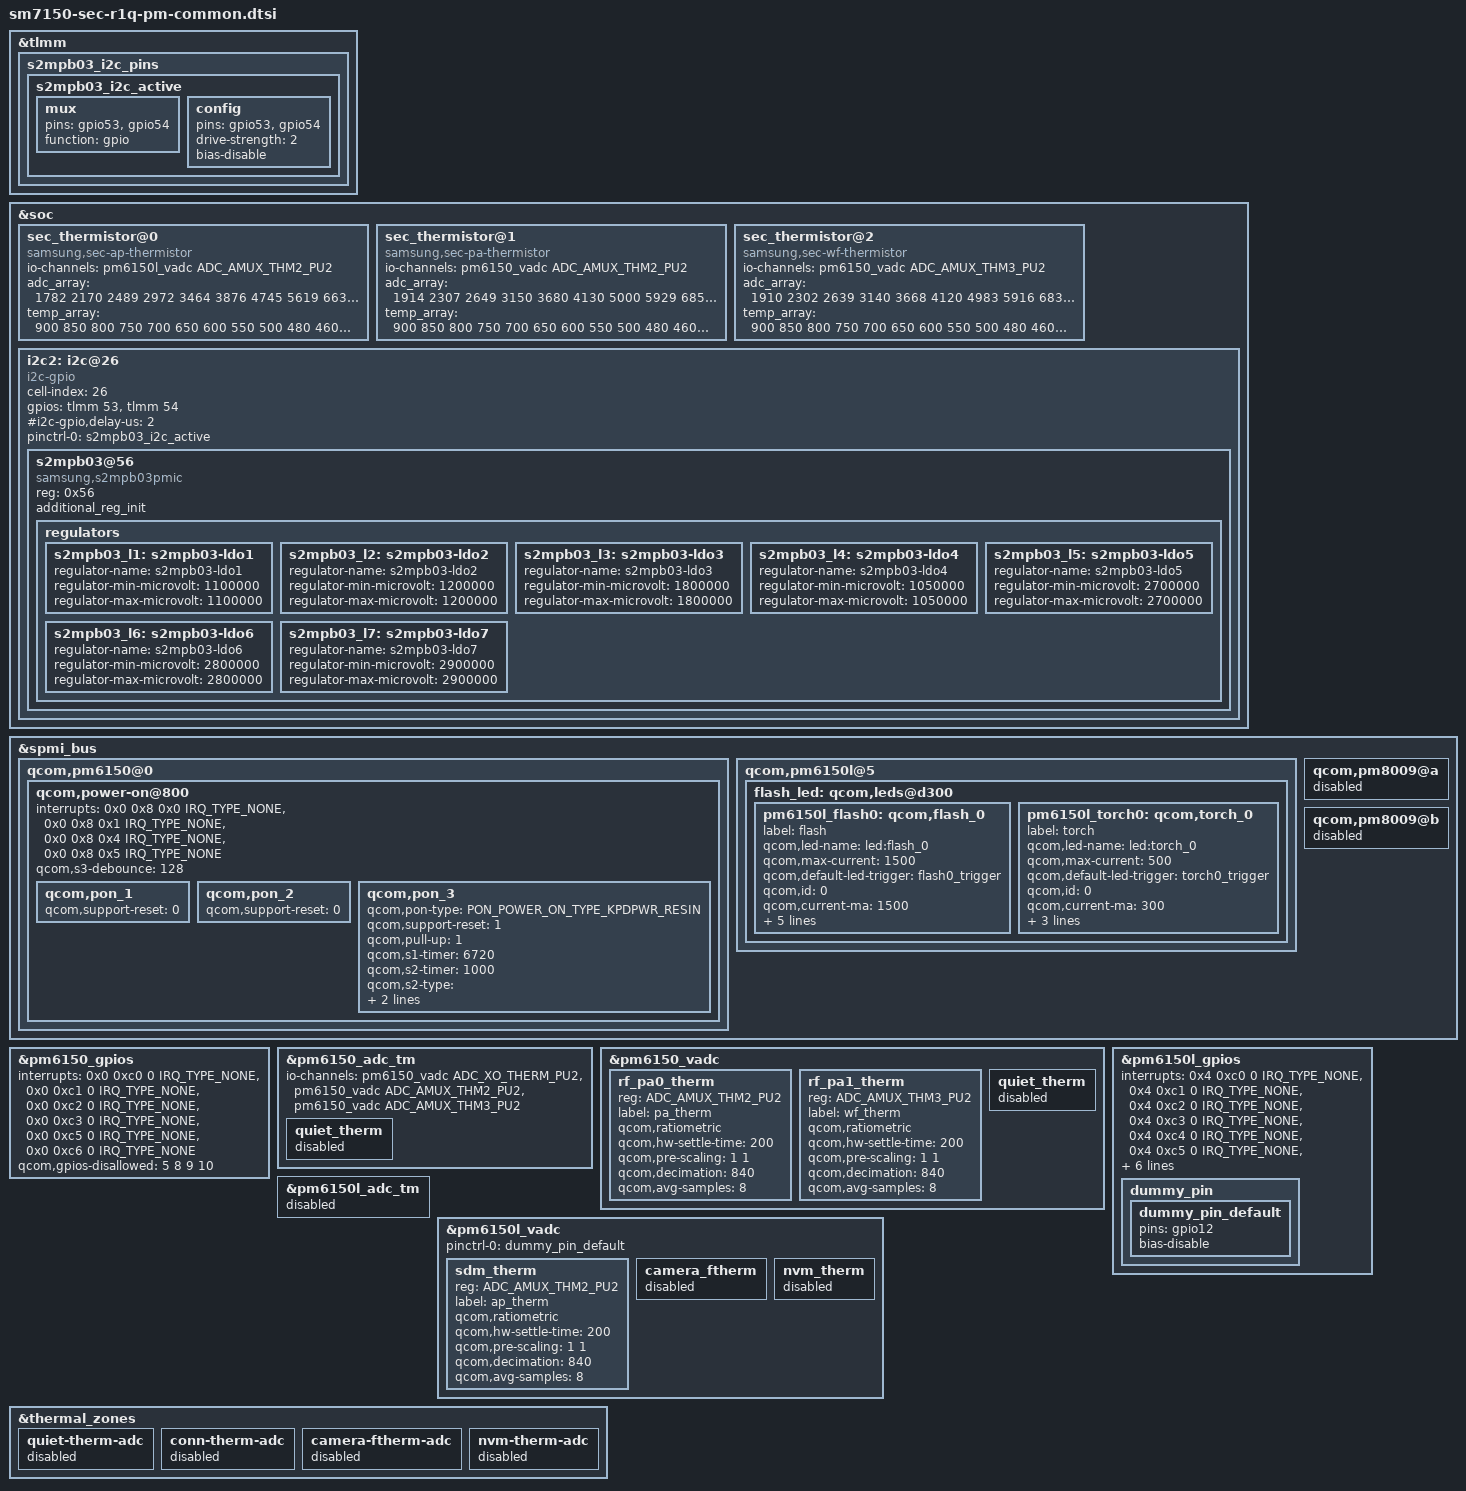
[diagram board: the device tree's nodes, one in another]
/* Copyright (c) 2018, The Linux Foundation. All rights reserved.
 *
 * This program is free software; you can redistribute it and/or modify
 * it under the terms of the GNU General Public License version 2 and
 * only version 2 as published by the Free Software Foundation.
 *
 * This program is distributed in the hope that it will be useful,
 * but WITHOUT ANY WARRANTY; without even the implied warranty of
 * MERCHANTABILITY or FITNESS FOR A PARTICULAR PURPOSE.  See the
 * GNU General Public License for more details.
 */
#include <dt-bindings/input/qcom,qpnp-power-on.h>

&tlmm {
	s2mpb03_i2c_pins {
		s2mpb03_i2c_active: s2mpb03_i2c_active {
			mux {
				pins = "gpio53", "gpio54";
				function = "gpio";
			};
			config {
				pins = "gpio53", "gpio54";
				drive-strength = <2>;
				bias-disable;
			};
		};
	};
};

&soc {
	/* AP Thermistor table */
	sec_thermistor@0 {
		compatible = "samsung,sec-ap-thermistor";
		status = "okay";
		io-channels = <&pm6150l_vadc ADC_AMUX_THM2_PU2>;
		io-channel-names = "ap_therm";
		adc_array = <1782 2170 2489 2972 3464 3876 4745
					5619 6633 7099 7520 7972 8464 9020 9592 10167 10771 11357 11753
					13464 15121 16708 18393 20103 21419 23021 24228 25379 26099>;
		temp_array = <900 850 800 750 700 650 600
					550 500 480 460 440 420 400 380 360 340 320 300
					250 200 150 100 50 0 (-50) (-100) (-150) (-200)>;
	};

	/* PA Thermistor table */
	sec_thermistor@1 {
		compatible = "samsung,sec-pa-thermistor";
		status = "okay";
		io-channels = <&pm6150_vadc ADC_AMUX_THM2_PU2>;
		io-channel-names = "pa_therm";
		adc_array = <1914 2307 2649 3150 3680 4130 5000
					5929 6853 7280 7731 8225 8693 9262 9914 10473 11055 11604 12445
					14125 15966 17690 19306 20877 22060 23411 24563 25536 26339>;
		temp_array = <900 850 800 750 700 650 600
					550 500 480 460 440 420 400 380 360 340 320 300
					250 200 150 100 50 0 (-50) (-100) (-150) (-200)>;
	};

	/* WiFi Thermistor table */
	sec_thermistor@2 {
		compatible = "samsung,sec-wf-thermistor";
		status = "okay";
		io-channels = <&pm6150_vadc ADC_AMUX_THM3_PU2>;
		io-channel-names = "wf_therm";
		adc_array = <1910 2302 2639 3140 3668 4120 4983
					5916 6835 7388 7240 8208 8675 9240 9891 10452 11032 11578 12433
					14098 15940 17663 19280 20850 22029 23413 24540 25516 26317>;
		temp_array = <900 850 800 750 700 650 600
					550 500 480 460 440 420 400 380 360 340 320 300
					250 200 150 100 50 0 (-50) (-100) (-150) (-200)>;
	};

	/* S2MPB03 Camera PMIC */
	i2c2: i2c@26 {
		cell-index = <26>;
		compatible = "i2c-gpio";
		gpios = <&tlmm 53 0 /* sda */
				&tlmm 54 0 /* scl */
		>;
		#i2c-gpio,delay-us = <2>;
		#address-cells = <1>;
		#size-cells = <0>;

		pinctrl-names = "default";
		pinctrl-0 = <&s2mpb03_i2c_active>;

		/* S2MPB03 Camera PMIC */
		s2mpb03@56 {
			compatible = "samsung,s2mpb03pmic";
			reg = <0x56>;
			additional_reg_init;

			regulators {
				s2mpb03_l1: s2mpb03-ldo1 {
					regulator-name = "s2mpb03-ldo1";
					regulator-min-microvolt = <1100000>;
					regulator-max-microvolt = <1100000>;
				};

				s2mpb03_l2: s2mpb03-ldo2 {
					regulator-name = "s2mpb03-ldo2";
					regulator-min-microvolt = <1200000>;
					regulator-max-microvolt = <1200000>;
				};

				s2mpb03_l3: s2mpb03-ldo3 {
					regulator-name = "s2mpb03-ldo3";
					regulator-min-microvolt = <1800000>;
					regulator-max-microvolt = <1800000>;
				};

				s2mpb03_l4: s2mpb03-ldo4 {
					regulator-name = "s2mpb03-ldo4";
					regulator-min-microvolt = <1050000>;
					regulator-max-microvolt = <1050000>;
				};

				s2mpb03_l5: s2mpb03-ldo5 {
					regulator-name = "s2mpb03-ldo5";
					regulator-min-microvolt = <2700000>;
					regulator-max-microvolt = <2700000>;
				};

				s2mpb03_l6: s2mpb03-ldo6 {
					regulator-name = "s2mpb03-ldo6";
					regulator-min-microvolt = <2800000>;
					regulator-max-microvolt = <2800000>;
				};

				s2mpb03_l7: s2mpb03-ldo7 {
					regulator-name = "s2mpb03-ldo7";
					regulator-min-microvolt = <2900000>;
					regulator-max-microvolt = <2900000>;
				};
			};
		};
	};
};

&spmi_bus {
	qcom,pm6150@0 {
		qcom,power-on@800 {
			interrupts = <0x0 0x8 0x0 IRQ_TYPE_NONE>,
					<0x0 0x8 0x1 IRQ_TYPE_NONE>,
					<0x0 0x8 0x4 IRQ_TYPE_NONE>,
					<0x0 0x8 0x5 IRQ_TYPE_NONE>;
			interrupt-names = "kpdpwr", "resin",
					"resin-bark", "kpdpwr-resin-bark";
			qcom,s3-debounce = <128>;

			qcom,pon_1 {
				qcom,support-reset = <0>;
			};

			qcom,pon_2 {
				qcom,support-reset = <0>;
			};

			qcom,pon_3 {
				qcom,pon-type = <PON_POWER_ON_TYPE_KPDPWR_RESIN>;
				qcom,support-reset = <1>;
				qcom,pull-up = <1>;
				qcom,s1-timer = <6720>;
				qcom,s2-timer = <1000>;
				qcom,s2-type = <PON_POWER_OFF_TYPE_DVDD_HARD_RESET>;
				qcom,use-bark;
			};
		};
	};

	qcom,pm6150l@5 {
		flash_led: qcom,leds@d300 {
			pm6150l_flash0: qcom,flash_0 {
				label = "flash";
				qcom,led-name = "led:flash_0";
				qcom,max-current = <1500>;
				qcom,default-led-trigger = "flash0_trigger";
				qcom,id = <0>;
				qcom,current-ma = <1500>;
				qcom,duration-ms = <1280>;
				qcom,ires-ua = <12500>;
				qcom,hdrm-voltage-mv = <325>;
				qcom,hdrm-vol-hi-lo-win-mv = <100>;
				qcom,record-current-ma = <200>;
			};
			pm6150l_torch0: qcom,torch_0 {
				label = "torch";
				qcom,led-name = "led:torch_0";
				qcom,max-current = <500>;
				qcom,default-led-trigger = "torch0_trigger";
				qcom,id = <0>;
				qcom,current-ma = <300>;
				qcom,ires-ua = <12500>;
				qcom,hdrm-voltage-mv = <325>;
				qcom,hdrm-vol-hi-lo-win-mv = <100>;
			};
		};			
	};	
    
	qcom,pm8009@a {
		status = "disabled";
	};
	qcom,pm8009@b {
		status = "disabled";
	};
};

&pm6150_gpios {
	interrupts = <0x0 0xc0 0 IRQ_TYPE_NONE>,
		<0x0 0xc1 0 IRQ_TYPE_NONE>,
		<0x0 0xc2 0 IRQ_TYPE_NONE>,
		<0x0 0xc3 0 IRQ_TYPE_NONE>,
		<0x0 0xc5 0 IRQ_TYPE_NONE>,
		<0x0 0xc6 0 IRQ_TYPE_NONE>;

	interrupt-names = "pm6150_gpio1", "pm6150_gpio2",
		"pm6150_gpio3", "pm6150_gpio4",
		"pm6150_gpio6",
		"pm6150_gpio7";
	qcom,gpios-disallowed = <5 8 9 10>;
};

&pm6150_adc_tm {
	io-channels = <&pm6150_vadc ADC_XO_THERM_PU2>,
			<&pm6150_vadc ADC_AMUX_THM2_PU2>,
			<&pm6150_vadc ADC_AMUX_THM3_PU2>;

	quiet_therm {
		status = "disabled";
	};
};

&pm6150_vadc {
	rf_pa0_therm {
		reg = <ADC_AMUX_THM2_PU2>;
		label = "pa_therm";
		qcom,ratiometric;
		qcom,hw-settle-time = <200>;
		qcom,pre-scaling = <1 1>;
		qcom,decimation = <840>;
		qcom,avg-samples = <8>;
	};

	rf_pa1_therm {
		reg = <ADC_AMUX_THM3_PU2>;
		label = "wf_therm";
		qcom,ratiometric;
		qcom,hw-settle-time = <200>;
		qcom,pre-scaling = <1 1>;
		qcom,decimation = <840>;
		qcom,avg-samples = <8>;
	};

	quiet_therm {
		status = "disabled";
	};
};

&pm6150l_gpios {
	interrupts = <0x4 0xc0 0 IRQ_TYPE_NONE>,
			<0x4 0xc1 0 IRQ_TYPE_NONE>,
			<0x4 0xc2 0 IRQ_TYPE_NONE>,
			<0x4 0xc3 0 IRQ_TYPE_NONE>,
			<0x4 0xc4 0 IRQ_TYPE_NONE>,
			<0x4 0xc5 0 IRQ_TYPE_NONE>,
			<0x4 0xc7 0 IRQ_TYPE_NONE>,
			<0x4 0xc8 0 IRQ_TYPE_NONE>,
			<0x4 0xc9 0 IRQ_TYPE_NONE>,
			<0x4 0xca 0 IRQ_TYPE_NONE>,
			<0x4 0xcb 0 IRQ_TYPE_NONE>;
	interrupt-names = "pm6150l_gpio1", "pm6150l_gpio2",
			"pm6150l_gpio3", "pm6150l_gpio4",
			"pm6150l_gpio5", "pm6150l_gpio6",
			"pm6150l_gpio8", "pm6150l_gpio9",
			"pm6150l_gpio10", "pm6150l_gpio11",
			"pm6150l_gpio12";
	qcom,gpios-disallowed = <7>;

	dummy_pin {
		dummy_pin_default: dummy_pin_default {
			pins = "gpio12";
			bias-disable;
		};
	};
};

&pm6150l_adc_tm {
	status = "disabled";
/*	/delete-property/ io-channels;

	conn_therm {
		status = "disabled";
	};
	camera_ftherm {
		status = "disabled";
	};
	nvm_therm {
		status = "disabled";
	}; */
};

&pm6150l_vadc {
	pinctrl-0 = <&dummy_pin_default>;

	sdm_therm {
		reg = <ADC_AMUX_THM2_PU2>;
		label = "ap_therm";
		qcom,ratiometric;
		qcom,hw-settle-time = <200>;
		qcom,pre-scaling = <1 1>;
		qcom,decimation = <840>;
		qcom,avg-samples = <8>;
	};

	camera_ftherm {
		status = "disabled";
	};
	nvm_therm {
		status = "disabled";
	};
};

&thermal_zones {
	quiet-therm-adc {
		status = "disabled";
	};
	conn-therm-adc {
		status = "disabled";
	};
	camera-ftherm-adc {
		status = "disabled";
	};
	nvm-therm-adc {
		status = "disabled";
	};
};
